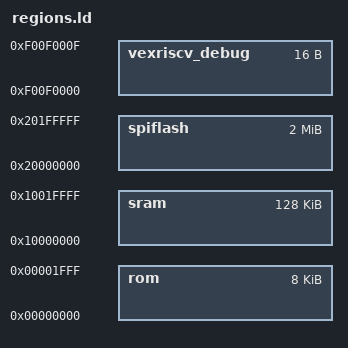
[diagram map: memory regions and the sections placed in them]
MEMORY {
	vexriscv_debug : ORIGIN = 0xf00f0000, LENGTH = 0x00000010
	sram : ORIGIN = 0x10000000, LENGTH = 0x00020000
	rom : ORIGIN = 0x00000000, LENGTH = 0x00002000
	spiflash : ORIGIN = 0x20000000, LENGTH = 0x00200000
}
